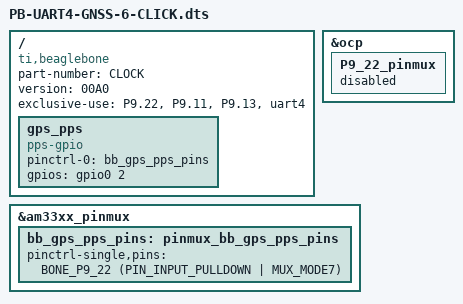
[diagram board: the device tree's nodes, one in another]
/dts-v1/;
/plugin/;

#include <dt-bindings/board/am335x-bbw-bbb-base.h>
#include <dt-bindings/gpio/gpio.h>
#include <dt-bindings/pinctrl/am33xx.h>

/ {
        compatible = "ti,beaglebone", "ti,beaglebone-black", "ti,beaglebone-green";

        /* identification */
        part-number = "CLOCK";
        version = "00A0";

        exclusive-use =
                "P9.22", "P9.11", "P9.13", "uart4"; // gps and pps

        fragment@0 {
                target = <&ocp>;
                __overlay__ {
                        P9_22_pinmux { status = "disabled"; };
                };
        };

        fragment@1 {
                target = <&am33xx_pinmux>;
                __overlay__ {
                        bb_gps_pps_pins: pinmux_bb_gps_pps_pins {
                                pinctrl-single,pins = <
                                        BONE_P9_22 (PIN_INPUT_PULLDOWN | MUX_MODE7)
                                >;
                        };

                };
        };

        fragment@2 {
                target-path = "/";
                __overlay__ {
                        gps_pps {
                                status = "okay";
                                compatible = "pps-gpio";
                                pinctrl-names = "default";
                                pinctrl-0 = <&bb_gps_pps_pins>;
                                gpios = <&gpio0 2 0>;
                        };
                };
        };

};

